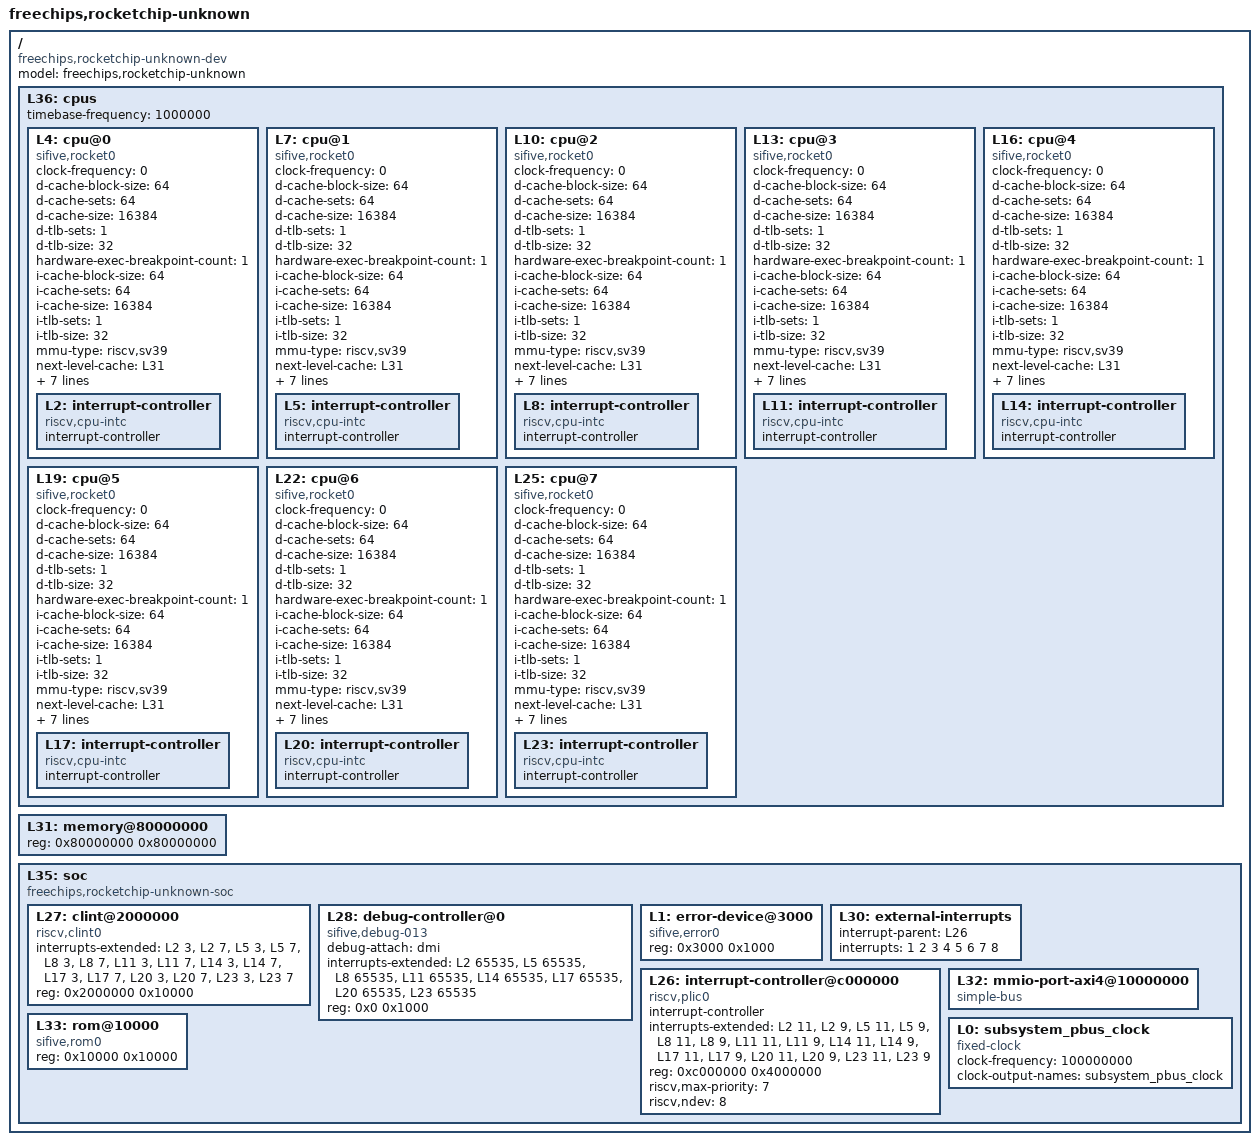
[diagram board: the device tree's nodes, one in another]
/dts-v1/;

/ {
	#address-cells = <1>;
	#size-cells = <1>;
	compatible = "freechips,rocketchip-unknown-dev";
	model = "freechips,rocketchip-unknown";
	L36: cpus {
		#address-cells = <1>;
		#size-cells = <0>;
		timebase-frequency = <1000000>;
		L4: cpu@0 {
			clock-frequency = <0>;
			compatible = "sifive,rocket0", "riscv";
			d-cache-block-size = <64>;
			d-cache-sets = <64>;
			d-cache-size = <16384>;
			d-tlb-sets = <1>;
			d-tlb-size = <32>;
			device_type = "cpu";
			hardware-exec-breakpoint-count = <1>;
			i-cache-block-size = <64>;
			i-cache-sets = <64>;
			i-cache-size = <16384>;
			i-tlb-sets = <1>;
			i-tlb-size = <32>;
			mmu-type = "riscv,sv39";
			next-level-cache = <&L31>;
			reg = <0x0>;
			riscv,isa = "rv64imafdczicsr_zifencei_zihpm_xrocket";
			riscv,pmpgranularity = <4>;
			riscv,pmpregions = <8>;
			status = "okay";
			timebase-frequency = <1000000>;
			tlb-split;
			L2: interrupt-controller {
				#interrupt-cells = <1>;
				compatible = "riscv,cpu-intc";
				interrupt-controller;
			};
		};
		L7: cpu@1 {
			clock-frequency = <0>;
			compatible = "sifive,rocket0", "riscv";
			d-cache-block-size = <64>;
			d-cache-sets = <64>;
			d-cache-size = <16384>;
			d-tlb-sets = <1>;
			d-tlb-size = <32>;
			device_type = "cpu";
			hardware-exec-breakpoint-count = <1>;
			i-cache-block-size = <64>;
			i-cache-sets = <64>;
			i-cache-size = <16384>;
			i-tlb-sets = <1>;
			i-tlb-size = <32>;
			mmu-type = "riscv,sv39";
			next-level-cache = <&L31>;
			reg = <0x1>;
			riscv,isa = "rv64imafdczicsr_zifencei_zihpm_xrocket";
			riscv,pmpgranularity = <4>;
			riscv,pmpregions = <8>;
			status = "okay";
			timebase-frequency = <1000000>;
			tlb-split;
			L5: interrupt-controller {
				#interrupt-cells = <1>;
				compatible = "riscv,cpu-intc";
				interrupt-controller;
			};
		};
		L10: cpu@2 {
			clock-frequency = <0>;
			compatible = "sifive,rocket0", "riscv";
			d-cache-block-size = <64>;
			d-cache-sets = <64>;
			d-cache-size = <16384>;
			d-tlb-sets = <1>;
			d-tlb-size = <32>;
			device_type = "cpu";
			hardware-exec-breakpoint-count = <1>;
			i-cache-block-size = <64>;
			i-cache-sets = <64>;
			i-cache-size = <16384>;
			i-tlb-sets = <1>;
			i-tlb-size = <32>;
			mmu-type = "riscv,sv39";
			next-level-cache = <&L31>;
			reg = <0x2>;
			riscv,isa = "rv64imafdczicsr_zifencei_zihpm_xrocket";
			riscv,pmpgranularity = <4>;
			riscv,pmpregions = <8>;
			status = "okay";
			timebase-frequency = <1000000>;
			tlb-split;
			L8: interrupt-controller {
				#interrupt-cells = <1>;
				compatible = "riscv,cpu-intc";
				interrupt-controller;
			};
		};
		L13: cpu@3 {
			clock-frequency = <0>;
			compatible = "sifive,rocket0", "riscv";
			d-cache-block-size = <64>;
			d-cache-sets = <64>;
			d-cache-size = <16384>;
			d-tlb-sets = <1>;
			d-tlb-size = <32>;
			device_type = "cpu";
			hardware-exec-breakpoint-count = <1>;
			i-cache-block-size = <64>;
			i-cache-sets = <64>;
			i-cache-size = <16384>;
			i-tlb-sets = <1>;
			i-tlb-size = <32>;
			mmu-type = "riscv,sv39";
			next-level-cache = <&L31>;
			reg = <0x3>;
			riscv,isa = "rv64imafdczicsr_zifencei_zihpm_xrocket";
			riscv,pmpgranularity = <4>;
			riscv,pmpregions = <8>;
			status = "okay";
			timebase-frequency = <1000000>;
			tlb-split;
			L11: interrupt-controller {
				#interrupt-cells = <1>;
				compatible = "riscv,cpu-intc";
				interrupt-controller;
			};
		};
		L16: cpu@4 {
			clock-frequency = <0>;
			compatible = "sifive,rocket0", "riscv";
			d-cache-block-size = <64>;
			d-cache-sets = <64>;
			d-cache-size = <16384>;
			d-tlb-sets = <1>;
			d-tlb-size = <32>;
			device_type = "cpu";
			hardware-exec-breakpoint-count = <1>;
			i-cache-block-size = <64>;
			i-cache-sets = <64>;
			i-cache-size = <16384>;
			i-tlb-sets = <1>;
			i-tlb-size = <32>;
			mmu-type = "riscv,sv39";
			next-level-cache = <&L31>;
			reg = <0x4>;
			riscv,isa = "rv64imafdczicsr_zifencei_zihpm_xrocket";
			riscv,pmpgranularity = <4>;
			riscv,pmpregions = <8>;
			status = "okay";
			timebase-frequency = <1000000>;
			tlb-split;
			L14: interrupt-controller {
				#interrupt-cells = <1>;
				compatible = "riscv,cpu-intc";
				interrupt-controller;
			};
		};
		L19: cpu@5 {
			clock-frequency = <0>;
			compatible = "sifive,rocket0", "riscv";
			d-cache-block-size = <64>;
			d-cache-sets = <64>;
			d-cache-size = <16384>;
			d-tlb-sets = <1>;
			d-tlb-size = <32>;
			device_type = "cpu";
			hardware-exec-breakpoint-count = <1>;
			i-cache-block-size = <64>;
			i-cache-sets = <64>;
			i-cache-size = <16384>;
			i-tlb-sets = <1>;
			i-tlb-size = <32>;
			mmu-type = "riscv,sv39";
			next-level-cache = <&L31>;
			reg = <0x5>;
			riscv,isa = "rv64imafdczicsr_zifencei_zihpm_xrocket";
			riscv,pmpgranularity = <4>;
			riscv,pmpregions = <8>;
			status = "okay";
			timebase-frequency = <1000000>;
			tlb-split;
			L17: interrupt-controller {
				#interrupt-cells = <1>;
				compatible = "riscv,cpu-intc";
				interrupt-controller;
			};
		};
		L22: cpu@6 {
			clock-frequency = <0>;
			compatible = "sifive,rocket0", "riscv";
			d-cache-block-size = <64>;
			d-cache-sets = <64>;
			d-cache-size = <16384>;
			d-tlb-sets = <1>;
			d-tlb-size = <32>;
			device_type = "cpu";
			hardware-exec-breakpoint-count = <1>;
			i-cache-block-size = <64>;
			i-cache-sets = <64>;
			i-cache-size = <16384>;
			i-tlb-sets = <1>;
			i-tlb-size = <32>;
			mmu-type = "riscv,sv39";
			next-level-cache = <&L31>;
			reg = <0x6>;
			riscv,isa = "rv64imafdczicsr_zifencei_zihpm_xrocket";
			riscv,pmpgranularity = <4>;
			riscv,pmpregions = <8>;
			status = "okay";
			timebase-frequency = <1000000>;
			tlb-split;
			L20: interrupt-controller {
				#interrupt-cells = <1>;
				compatible = "riscv,cpu-intc";
				interrupt-controller;
			};
		};
		L25: cpu@7 {
			clock-frequency = <0>;
			compatible = "sifive,rocket0", "riscv";
			d-cache-block-size = <64>;
			d-cache-sets = <64>;
			d-cache-size = <16384>;
			d-tlb-sets = <1>;
			d-tlb-size = <32>;
			device_type = "cpu";
			hardware-exec-breakpoint-count = <1>;
			i-cache-block-size = <64>;
			i-cache-sets = <64>;
			i-cache-size = <16384>;
			i-tlb-sets = <1>;
			i-tlb-size = <32>;
			mmu-type = "riscv,sv39";
			next-level-cache = <&L31>;
			reg = <0x7>;
			riscv,isa = "rv64imafdczicsr_zifencei_zihpm_xrocket";
			riscv,pmpgranularity = <4>;
			riscv,pmpregions = <8>;
			status = "okay";
			timebase-frequency = <1000000>;
			tlb-split;
			L23: interrupt-controller {
				#interrupt-cells = <1>;
				compatible = "riscv,cpu-intc";
				interrupt-controller;
			};
		};
	};
	L31: memory@80000000 {
		device_type = "memory";
		reg = <0x80000000 0x80000000>;
	};
	L35: soc {
		#address-cells = <1>;
		#size-cells = <1>;
		compatible = "freechips,rocketchip-unknown-soc", "simple-bus";
		ranges;
		L27: clint@2000000 {
			compatible = "riscv,clint0";
			interrupts-extended = <&L2 3 &L2 7 &L5 3 &L5 7 &L8 3 &L8 7 &L11 3 &L11 7 &L14 3 &L14 7 &L17 3 &L17 7 &L20 3 &L20 7 &L23 3 &L23 7>;
			reg = <0x2000000 0x10000>;
			reg-names = "control";
		};
		L28: debug-controller@0 {
			compatible = "sifive,debug-013", "riscv,debug-013";
			debug-attach = "dmi";
			interrupts-extended = <&L2 65535 &L5 65535 &L8 65535 &L11 65535 &L14 65535 &L17 65535 &L20 65535 &L23 65535>;
			reg = <0x0 0x1000>;
			reg-names = "control";
		};
		L1: error-device@3000 {
			compatible = "sifive,error0";
			reg = <0x3000 0x1000>;
		};
		L30: external-interrupts {
			interrupt-parent = <&L26>;
			interrupts = <1 2 3 4 5 6 7 8>;
		};
		L26: interrupt-controller@c000000 {
			#interrupt-cells = <1>;
			compatible = "riscv,plic0";
			interrupt-controller;
			interrupts-extended = <&L2 11 &L2 9 &L5 11 &L5 9 &L8 11 &L8 9 &L11 11 &L11 9 &L14 11 &L14 9 &L17 11 &L17 9 &L20 11 &L20 9 &L23 11 &L23 9>;
			reg = <0xc000000 0x4000000>;
			reg-names = "control";
			riscv,max-priority = <7>;
			riscv,ndev = <8>;
		};
		L32: mmio-port-axi4@10000000 {
			#address-cells = <1>;
			#size-cells = <1>;
			compatible = "simple-bus";
			ranges = <0x10000000 0x10000000 0x70000000>;
		};
		L33: rom@10000 {
			compatible = "sifive,rom0";
			reg = <0x10000 0x10000>;
			reg-names = "mem";
		};
		L0: subsystem_pbus_clock {
			#clock-cells = <0>;
			clock-frequency = <100000000>;
			clock-output-names = "subsystem_pbus_clock";
			compatible = "fixed-clock";
		};
	};
};
